# STM32WL5x_CM0P register map
File version: 1.5
CPU: CM0 r0p1, little endian, MPU, no FPU, 4 interrupt priority bits
Registers are 32-bit, read-write, reset 0x0 unless marked. A register's access mark holds for its fields unless they carry their own. Offsets are from the block's base; [hi:lo] are bit positions; {n}, {i} and the like mark numbered series.

## TZSC — Global TrustZone Controller
Base 0x58004400
0x00 TZSC_CR — TZSC control register
  [0] LCK
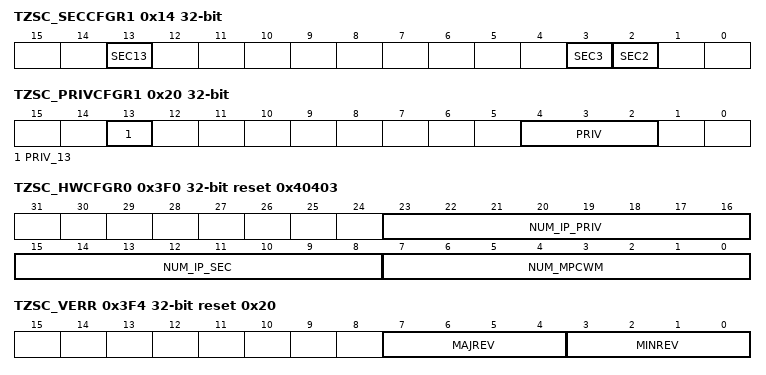
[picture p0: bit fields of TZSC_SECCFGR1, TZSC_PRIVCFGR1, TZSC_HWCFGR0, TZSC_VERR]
0x14 TZSC_SECCFGR1 — TZSC security configuration register
  [13] SEC13, [3] SEC3, [2] SEC2
0x20 TZSC_PRIVCFGR1 — TZSC privilege configuration register 1
  [13] PRIV_13 — Peripheral privilege access mode enabled bit
  [4:2] PRIV — Peripheral privilege access mode enabled bit
{0x130+8i} TZSC_MPCWM{i}_UPWMR reset 0xFFF0000 (i=0..2) — Unprivileged Water Mark {i} register
  [27:16] UPWM1LGTH
0x134 TZSC_MPCWM0_UPWWMR reset 0xFFF0000 — Unprivileged Writable Water Mark 0 register
  [27:16] UPWWM1LGTH — Define the length of Flash Unprivileged Writable area, in 2
0x3F0 TZSC_HWCFGR0 ro reset 0x40403 — HW configuration register 0
  [23:16] NUM_IP_PRIV, [15:8] NUM_IP_SEC, [7:0] NUM_MPCWM
0x3F4 TZSC_VERR ro reset 0x20 — IP version register
  [7:4] MAJREV, [3:0] MINREV
0x3F8 TZSC_IPIDR ro reset 0x100062 — IP identification register
  [31:0] ID — IP identification
0x3FC TZSC_SIDR ro reset 0xA3C5DD01 — IP size identification register
  [31:0] SID — IP size identification

## TZIC — TrustZone Interrupt Control
Base 0x58004800
0x04 IER1 ro reset 0xFFFFFFFF — TZIC interrupt mask register 1
0x14 MISR1 ro — TZIC status register 1
0x28 ICR1 ro — TZIC interrupt flag clear register
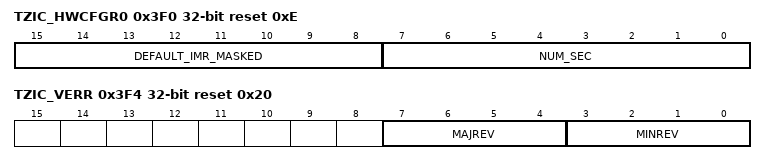
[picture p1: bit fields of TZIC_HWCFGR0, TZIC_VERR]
0x3F0 TZIC_HWCFGR0 ro reset 0xE — HW configuration register 0
  [15:8] DEFAULT_IMR_MASKED, [7:0] NUM_SEC
0x3F4 TZIC_VERR ro reset 0x20 — IP version register
  [7:4] MAJREV, [3:0] MINREV
0x3F8 TZIC_IPIDR ro reset 0x100063 — IP identification register
  [31:0] ID — IP identification
0x3FC TZIC_SIDR ro reset 0xA3C5DD01 — IP size identification register
  [31:0] SID — IP size identification

## SPI1 — Serial peripheral interface/Inter-IC sound
Base 0x40013000
Same registers: SPI2 0x40003800, SPI3 0x58010000
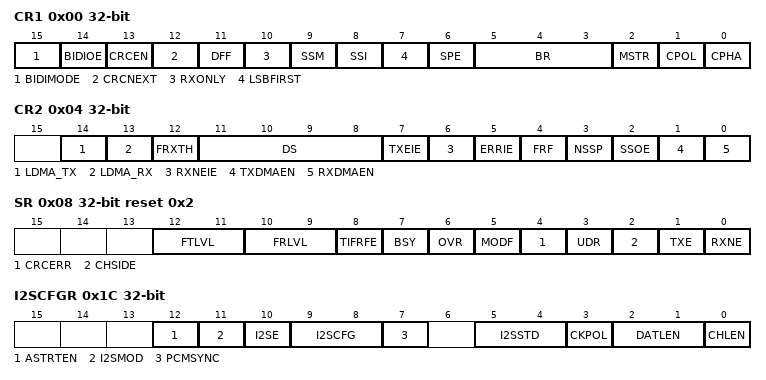
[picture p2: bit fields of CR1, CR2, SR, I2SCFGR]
0x00 CR1 — control register 1
  [15] BIDIMODE — Bidirectional data mode enable
  [14] BIDIOE — Output enable in bidirectional mode
  [13] CRCEN — Hardware CRC calculation enable
  [12] CRCNEXT — CRC transfer next
  [11] DFF — Data frame format
  [10] RXONLY — Receive only
  [9] SSM — Software slave management
  [8] SSI — Internal slave select
  [7] LSBFIRST — Frame format
  [6] SPE — SPI enable
  [5:3] BR — Baud rate control
  [2] MSTR — Master selection
  [1] CPOL — Clock polarity
  [0] CPHA — Clock phase
0x04 CR2 — control register 2
  [14] LDMA_TX — Last DMA transfer for transmission
  [13] LDMA_RX — Last DMA transfer for reception
  [12] FRXTH — FIFO reception threshold
  [11:8] DS — Data size
  [7] TXEIE — Tx buffer empty interrupt enable
  [6] RXNEIE — RX buffer not empty interrupt enable
  [5] ERRIE — Error interrupt enable
  [4] FRF — Frame format
  [3] NSSP — NSS pulse management
  [2] SSOE — SS output enable
  [1] TXDMAEN — Tx buffer DMA enable
  [0] RXDMAEN — Rx buffer DMA enable
0x08 SR access per field reset 0x2 — status register
  [12:11] FTLVL ro — FIFO transmission level
  [10:9] FRLVL ro — FIFO reception level
  [8] TIFRFE ro — TI frame format error
  [7] BSY ro — Busy flag
  [6] OVR ro — Overrun flag
  [5] MODF ro — Mode fault
  [4] CRCERR rw — CRC error flag
  [3] UDR ro
  [2] CHSIDE ro
  [1] TXE ro — Transmit buffer empty
  [0] RXNE ro — Receive buffer not empty
0x0C DR — data register
  [15:0] DR — Data register
0x10 CRCPR reset 0x7 — CRC polynomial register
  [15:0] CRCPOLY
0x14 RXCRCR ro — RX CRC register
  [15:0] RxCRC
0x18 TXCRCR ro — TX CRC register
  [15:0] TxCRC
0x1C I2SCFGR — configuration register
  [12] ASTRTEN, [11] I2SMOD, [10] I2SE, [9:8] I2SCFG, [7] PCMSYNC, [5:4] I2SSTD, [3] CKPOL, [2:1] DATLEN, [0] CHLEN
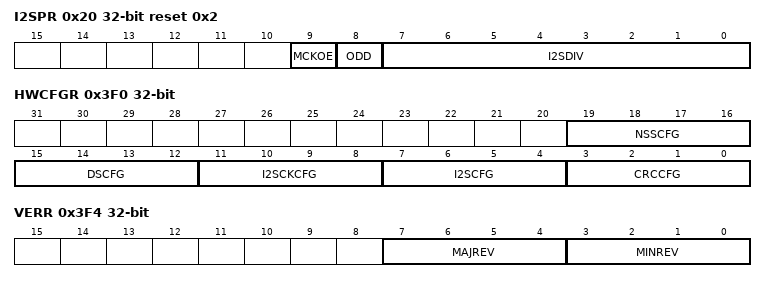
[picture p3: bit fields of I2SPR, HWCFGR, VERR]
0x20 I2SPR reset 0x2 — prescaler register
  [9] MCKOE, [8] ODD, [7:0] I2SDIV
0x3F0 HWCFGR ro — SPIx_I2S hardware configuration register
  [19:16] NSSCFG, [15:12] DSCFG, [11:8] I2SCKCFG, [7:4] I2SCFG, [3:0] CRCCFG
0x3F4 VERR ro — SPIx_I2S IP version register
  [7:4] MAJREV, [3:0] MINREV
0x3F8 IPIDR ro reset 0x130021 — SPIx_I2S IP identification reg
  [31:0] ID
0x3FC SIDR ro reset 0xA3C5DD00 — SPIx_I2S size identification register
  [31:0] SID
